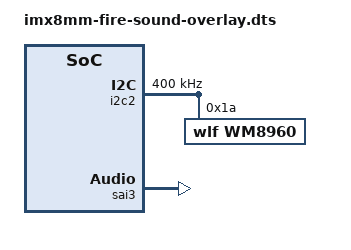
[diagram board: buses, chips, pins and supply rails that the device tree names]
/*
 * Copyright (C) 2021 - All Rights Reserved by 
 * filename : imx8mm-fire-sound-overlay.dts
 * brief : Device Tree overlay for ebf imx8mm sound device
 * author : embedfire
 * date : 2021-12-04 
 * version : A001
 */

/dts-v1/;
/plugin/;

#include "../imx8mm-pinfunc.h"
#include "dt-bindings/gpio/gpio.h"
#include "dt-bindings/clock/imx8mm-clock.h"

/ {
	fragment@0 {
		target-path = "/";	
		__overlay__ {
			sound-wm8960 {
				compatible = "fsl,imx7d-evk-wm8960", "fsl,imx-audio-wm8960";
				model = "wm8960-audio";
				cpu-dai = <&sai3>;
				audio-codec = <&wm8960>;
				codec-master;
				/*
				 * hp-det = <hp-det-pin hp-det-polarity>;
				 * hp-det-pin: JD1 JD2  or JD3
				 * hp-det-polarity = 0: hp detect high for headphone
				 * hp-det-polarity = 1: hp detect high for speaker
				 */
				hp-det = <3 1>;
				audio-routing =
					"Headphone Jack", "HP_L",
					"Headphone Jack", "HP_R",
					"Ext Spk", "SPK_LP",
					"Ext Spk", "SPK_LN",
					"Ext Spk", "SPK_RP",
					"Ext Spk", "SPK_RN",
					"LINPUT1", "Mic Jack",
					"RINPUT1", "Main MIC",
					"RINPUT2", "Main MIC",
					"Mic Jack", "MICB",
					"Main MIC", "MICB",
					"Playback","CPU-Playback",
					"CPU-Capture", "Capture";
				status = "okay";
			};
		};
	};

	fragment@1 {
		target = <&i2c2>;
		__overlay__ {
			clock-frequency = <400000>;
			pinctrl-names = "default";
			pinctrl-0 = <&pinctrl_i2c2>;
			status = "okay";

                        #address-cells = <1>;
                        #size-cells = <0>;	

			wm8960: codec@1a {
				compatible = "wlf,wm8960";
				reg = <0x1a>;
				clocks = <&clk IMX8MM_CLK_SAI3_ROOT>;
				clock-names = "mclk";
				wlf,shared-lrclk;
				status = "okay";
			};
		};
	};

	fragment@2 {
		target = <&sai3>;
		__overlay__ {
			pinctrl-names = "default";
			pinctrl-0 = <&pinctrl_sai3>;
			assigned-clocks = <&clk IMX8MM_CLK_SAI3>;
			assigned-clock-parents = <&clk IMX8MM_AUDIO_PLL1_OUT>;
			assigned-clock-rates = <12288000>, <24576000>;
			status = "okay";
		};
	};

	fragment@3 {
		target= <&iomuxc>;
		__overlay__{
			pinctrl_i2c2: i2c2grp {
				fsl,pins = <
					MX8MM_IOMUXC_I2C2_SCL_I2C2_SCL                  0x400001c3
					MX8MM_IOMUXC_I2C2_SDA_I2C2_SDA                  0x400001c3
				>;
			};

			pinctrl_sai3: sai3grp {
				fsl,pins = <
					MX8MM_IOMUXC_SAI3_TXFS_SAI3_TX_SYNC     0xd6
					MX8MM_IOMUXC_SAI3_TXC_SAI3_TX_BCLK      0xd6
					MX8MM_IOMUXC_SAI3_MCLK_SAI3_MCLK        0xd6
					MX8MM_IOMUXC_SAI3_TXD_SAI3_TX_DATA0     0xd6
					MX8MM_IOMUXC_SAI3_RXD_SAI3_RX_DATA0     0xd6
				>;
			};
		};
	};
};
